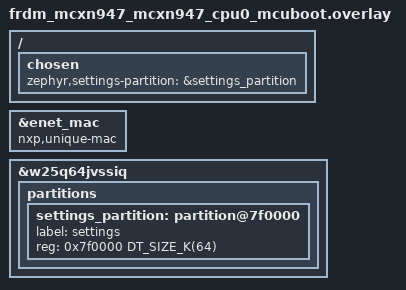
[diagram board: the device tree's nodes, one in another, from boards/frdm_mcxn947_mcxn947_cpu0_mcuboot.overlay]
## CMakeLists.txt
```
# SPDX-License-Identifier: Apache-2.0

cmake_minimum_required(VERSION 3.20.0)

find_package(Zephyr REQUIRED HINTS $ENV{ZEPHYR_BASE})
project(mqtt_tls)

# boards/<board>_mcuboot.overlay moves the settings into a partition that is
# only free when MCUboot owns the flash layout. Without the bootloader the
# image would be linked over it.
if(FILE_SUFFIX STREQUAL "mcuboot" AND NOT CONFIG_BOOTLOADER_MCUBOOT)
  message(FATAL_ERROR
    "FILE_SUFFIX=mcuboot needs CONFIG_BOOTLOADER_MCUBOOT: build with --sysbuild, "
    "or add -DEXTRA_CONF_FILE=overlay-mcuboot.conf for an existing MCUboot.")
endif()

target_sources(app PRIVATE
  src/main.c
  src/net_wait.c
  src/mqtt_app.c
  src/device_id.c
  src/commands.c
  src/config.c
  src/log_mqtt.c
  src/mgmt.c
)
target_sources_ifdef(CONFIG_APP_WATCHDOG app PRIVATE src/watchdog.c)

if(CONFIG_APP_MQTT_TLS)
  target_sources(app PRIVATE src/tls_creds.c)
  # tls_creds.c parses the credentials with mbedTLS at boot.
  target_link_libraries(app PRIVATE mbedTLS)

  # Embed the TLS credentials named in Kconfig into the image. Each file is
  # turned into a C byte list (<name>.inc) that src/tls_creds.c includes.
  # Relative paths are resolved against the application directory.
  # PEM files get a NUL terminator appended in C, which mbedTLS requires to
  # recognise the PEM format; DER files (*.der) are embedded as-is.
  set(gen_dir ${ZEPHYR_BINARY_DIR}/include/generated/app_creds)

  function(app_embed_credential kconfig_value name required)
    if("${kconfig_value}" STREQUAL "")
      if(required)
        message(FATAL_ERROR "${name}: no credential file configured")
      endif()
      return()
    endif()

    if(IS_ABSOLUTE "${kconfig_value}")
      set(path "${kconfig_value}")
    else()
      set(path "${APPLICATION_SOURCE_DIR}/${kconfig_value}")
    endif()

    if(NOT EXISTS "${path}")
      message(FATAL_ERROR
        "${name}: credential file '${path}' does not exist.\n"
        "Set the matching CONFIG_APP_MQTT_TLS_* option, or generate "
        "development credentials with apps/mqtt_tls/scripts/gen_dev_certs.sh.")
    endif()

    string(TOLOWER "${name}" lname)
    generate_inc_file_for_target(app "${path}" "${gen_dir}/${lname}.inc")
    target_compile_definitions(app PRIVATE APP_HAVE_${name}=1)

    get_filename_component(ext "${path}" LAST_EXT)
    string(TOLOWER "${ext}" ext)
    if(NOT ext STREQUAL ".der")
      target_compile_definitions(app PRIVATE APP_${name}_IS_PEM=1)
    endif()
  endfunction()

  app_embed_credential("${CONFIG_APP_MQTT_TLS_CA_CERT_FILE}" CA_CERT TRUE)

  if(CONFIG_APP_MQTT_TLS_CLIENT_AUTH)
    app_embed_credential("${CONFIG_APP_MQTT_TLS_CLIENT_CERT_FILE}" CLIENT_CERT TRUE)
    app_embed_credential("${CONFIG_APP_MQTT_TLS_CLIENT_KEY_FILE}" CLIENT_KEY TRUE)
  endif()

  target_include_directories(app PRIVATE ${gen_dir})
endif()
```

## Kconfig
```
# SPDX-License-Identifier: Apache-2.0

mainmenu "MQTT over Ethernet + TLS application"

menu "MQTT application"

config APP_MQTT_BROKER_HOSTNAME
	string "Broker host name or IPv4 address"
	default "test.mosquitto.org"
	help
	  Resolved with DNS before every connection attempt, so a broker that
	  moves to a new address is picked up on the next reconnect.

config APP_MQTT_BROKER_PORT
	int "Broker TCP port"
	default 8883 if APP_MQTT_TLS
	default 1883
	range 1 65535

config APP_MQTT_CLIENT_ID
	string "MQTT client identifier"
	default ""
	help
	  Leave empty to derive a stable identifier from the MCU's unique
	  device ID: APP_MQTT_CLIENT_ID_PREFIX followed by 20 base32
	  characters (the 96-bit STM32 UID as is; longer UIDs, such as the
	  128-bit NXP MCX UID, condensed to 96 bits with SHA-256), so every
	  board gets its own id without per-device configuration. Must not contain '+', '#' or
	  '/', since it is also a topic level.

config APP_MQTT_CLIENT_ID_PREFIX
	string "Prefix of the derived client identifier"
	default "z"
	help
	  MQTT 3.1.1 brokers are only required to accept client identifiers
	  of 1-23 alphanumeric characters. With a 20-character device ID, a
	  prefix of up to 3 letters or digits stays within that limit. Most
	  brokers accept longer identifiers.

config APP_MQTT_TOPIC_ROOT
	string "Root of the device's topic tree"
	default "bacnet-uc"
	help
	  Topics are "<root>/<client id>/status", ".../info", ".../telemetry",
	  ".../cmd" and ".../event". May contain '/', but no wildcards and no
	  leading '$'.

	  Commands on ".../cmd" must be published without the retain flag:
	  retained commands are ignored, because the broker would replay them
	  after every reconnect.

config APP_MQTT_USERNAME
	string "User name (empty: none)"
	default ""

config APP_MQTT_PASSWORD
	string "Password (empty: none)"
	default ""
	help
	  Requires APP_MQTT_USERNAME (MQTT 3.1.1). Stored in the firmware
	  image in clear text, and sent in clear text on the wire unless both
	  APP_MQTT_TLS and APP_MQTT_TLS_PEER_VERIFY are enabled. Prefer client
	  certificates (APP_MQTT_TLS_CLIENT_AUTH) where the broker supports
	  them.

config APP_MQTT_PUBLISH_INTERVAL_SEC
	int "Telemetry publish interval (seconds)"
	default 10
	range 1 86400

config APP_MQTT_PUBLISH_QOS
	int "QoS of telemetry messages"
	default 1
	range 0 1
	help
	  QoS 1 makes the broker acknowledge each message and gives
	  at-least-once delivery from the broker to its subscribers. The
	  device itself keeps no outgoing queue and uses clean sessions, so a
	  message still in flight when the connection drops is lost either
	  way. QoS 2 is not offered for the same reason.

config APP_MQTT_CONNACK_TIMEOUT_MS
	int "Time to wait for CONNACK or SUBACK (ms)"
	default 10000
	range 1000 120000
	help
	  Applies after the TCP/TLS connection is up. The TCP connect and the
	  TLS handshake are bounded separately by
	  CONFIG_NET_SOCKETS_CONNECT_TIMEOUT and
	  CONFIG_NET_SOCKETS_TLS_CONNECT_TIMEOUT.

config APP_MQTT_RECONNECT_MIN_MS
	int "Initial reconnect back-off (ms)"
	default 1000
	range 100 600000

config APP_MQTT_RECONNECT_MAX_MS
	int "Maximum reconnect back-off (ms)"
	default 60000
	range 100 600000

config APP_MQTT_BUFFER_SIZE
	int "MQTT RX and TX buffer size (bytes)"
	default 2048
	range 1024 65535
	help
	  Upper bound for one outgoing MQTT packet and for the fixed and
	  variable header of an incoming one. Incoming payloads are read
	  separately (see APP_MQTT_MAX_PAYLOAD_SIZE).

config APP_MQTT_MAX_PAYLOAD_SIZE
	int "Largest command payload that is processed (bytes)"
	default 128
	range 1 4096
	help
	  Longer payloads on the command topic are read and discarded so the
	  connection stays in sync.

config APP_MQTT_TLS
	bool "Use TLS (MQTTS)"
	default y
	depends on MQTT_LIB_TLS

if APP_MQTT_TLS

config APP_MQTT_TLS_CA_CERT_FILE
	string "CA certificate used to verify the broker (PEM or .der)"
	default "certs/mosquitto.org.crt"
	help
	  Path is relative to the application directory unless absolute.
	  The default is the CA of the public test broker test.mosquitto.org.

	  Must be signed with SHA-256 or stronger: SHA-1 is not built in, so
	  roots that are self-signed with SHA-1 (e.g. "DigiCert Global Root
	  CA") cannot be loaded. Use a SHA-256 root or the SHA-256-signed
	  intermediate as trust anchor instead. The file is parsed at boot and
	  errors are reported there.

config APP_MQTT_TLS_PEER_VERIFY
	bool "Verify the broker certificate"
	default y
	help
	  Checks the broker's certificate chain against the CA and its name
	  against APP_MQTT_TLS_HOSTNAME. Validity dates are NOT checked
	  (CONFIG_MBEDTLS_HAVE_TIME_DATE is off, as the board has no trusted
	  clock at boot), so expired certificates are accepted.

	  Disabling this makes the connection vulnerable to
	  man-in-the-middle attacks. Only for bring-up.

config APP_MQTT_TLS_HOSTNAME
	string "Expected host name in the broker certificate, and SNI"
	default ""
	help
	  Sent as TLS Server Name Indication and matched against the broker
	  certificate. Leave empty to use APP_MQTT_BROKER_HOSTNAME. Set it
	  when the broker is addressed by IP address: an IP literal is then
	  sent as SNI, which RFC 6066 forbids and multi-tenant cloud brokers
	  reject.

config APP_MQTT_TLS_CLIENT_AUTH
	bool "Authenticate with a client certificate (mutual TLS)"

config APP_MQTT_TLS_CLIENT_CERT_FILE
	string "Client certificate (PEM or .der)"
	depends on APP_MQTT_TLS_CLIENT_AUTH
	default "certs/dev/client.crt"
	help
	  The default matches the output of scripts/gen_dev_certs.sh.

config APP_MQTT_TLS_CLIENT_KEY_FILE
	string "Client private key (unencrypted PEM or .der)"
	depends on APP_MQTT_TLS_CLIENT_AUTH
	default "certs/dev/client.key"
	help
	  The default matches the output of scripts/gen_dev_certs.sh.

	  The key is stored unencrypted in flash, and in the build directory
	  (zephyr/include/generated/app_creds). Protect it with flash read-out
	  protection (RDP) on production parts, or move it into a secure
	  element.

endif # APP_MQTT_TLS

config APP_WAIT_FOR_NETWORK
	bool "Wait for an IPv4 address before connecting"
	default y
	depends on NET_CONNECTION_MANAGER
	help
	  Uses the connection manager to wait until the default interface is
	  up and has an IPv4 address, and drops the MQTT session when the
	  network goes away.

config APP_WATCHDOG
	bool "Reboot if the main loop stalls"
	default y if $(dt_alias_enabled,watchdog0)
	depends on TASK_WDT
	help
	  Uses a task watchdog channel, backed by the hardware watchdog.
	  Every blocking call in the application is bounded well below the
	  timeout, so a reset means a genuine wedge.

config APP_WATCHDOG_TIMEOUT_SEC
	int "Watchdog timeout (seconds)"
	depends on APP_WATCHDOG
	default 120
	range 60 3600

config APP_CONFIG_FALLBACK_ATTEMPTS
	int "Connection attempts before new settings fall back"
	default 5
	range 1 100
	help
	  After a change of the broker, credentials, TLS host name, topic root
	  or keep-alive (MQTT config_set or SMP settings), the new configuration
	  is on trial. If it does not reach "online" within this many
	  connection attempts, the stored settings roll back to the last known
	  good configuration (or to the Kconfig defaults if none has worked
	  yet). The counter survives reboots.

config APP_LOG_MQTT
	bool "Publish log lines over MQTT"
	default y
	depends on LOG
	select LOG_OUTPUT
	help
	  Log backend that keeps recent lines in RAM for <root>/<id>/log and
	  the "logs" command. Lines are only captured if their module was
	  compiled in at that level (CONFIG_LOG_DEFAULT_LEVEL, CONFIG_APP_LOG_LEVEL):
	  mqtt/log_level can lower the threshold at run time, but not raise it
	  beyond what was compiled in.

config APP_LOG_MQTT_LEVEL
	int "Default level of the MQTT log topic (1=err 2=wrn 3=inf 4=dbg)"
	default 2
	range 1 4
	help
	  Log lines at or above this level are captured in RAM and published
	  on <root>/<id>/log. Changeable at run time (mqtt/log_level).

config APP_LOG_MQTT_RING_SIZE
	int "Log lines kept in RAM"
	default 32
	range 4 256

config APP_LOG_MQTT_RATE
	int "Log lines published per second (sustained)"
	default 5
	range 1 100

config APP_LOG_MQTT_BURST
	int "Log lines published in a burst"
	default 20
	range 1 256

config APP_SMP
	bool "Remote management over SMP (MCUmgr) on UDP"
	default y
	depends on NET_UDP && NET_SOCKETS
	imply NET_BUF
	imply ZCBOR
	imply MCUMGR
	imply MCUMGR_TRANSPORT_UDP
	imply MCUMGR_TRANSPORT_UDP_IPV4
	imply MCUMGR_GRP_OS
	imply MCUMGR_GRP_OS_INFO
	imply MCUMGR_GRP_OS_MCUMGR_PARAMS
	imply MCUMGR_GRP_SETTINGS
	imply MCUMGR_MGMT_NOTIFICATION_HOOKS
	imply MCUMGR_GRP_SETTINGS_ACCESS_HOOK
	help
	  SMP server on UDP port 1337 (CONFIG_MCUMGR_TRANSPORT_UDP_PORT), as
	  in the BACnet firmware: OS group (echo, reset, info), settings group
	  (runtime configuration, subtree mqtt/) and, in the MCUboot variant,
	  the image group for firmware updates. SMP over UDP is not
	  authenticated: keep it on the management network.

if APP_SMP && MCUMGR

# A full Ethernet payload: image uploads need fewer round trips, and smpmgr
# sizes its upload chunks from the MTU reported by mcumgr params.
configdefault MCUMGR_TRANSPORT_UDP_MTU
	default 1472

# mcumgr params reports this as buf_size, and clients size their frames from
# it: it must not exceed the UDP MTU.
configdefault MCUMGR_TRANSPORT_NETBUF_SIZE
	default 1472

configdefault MCUMGR_TRANSPORT_WORKQUEUE_STACK_SIZE
	default 3072

configdefault MCUMGR_GRP_SETTINGS_NAME_LEN
	default 32

configdefault MCUMGR_GRP_SETTINGS_VALUE_LEN
	default 64

endif

config APP_MCUBOOT_CONFIRM_TIMEOUT_SEC
	int "Seconds a test image has to reach online before it is reverted"
	depends on BOOTLOADER_MCUBOOT
	default 600
	range 60 86400

# Without sysbuild (overlay-mcuboot.conf with a separately built MCUboot) the
# app has to match the bootloader's swap mode; same choice as Kconfig.sysbuild.
choice MCUBOOT_BOOTLOADER_MODE
	default MCUBOOT_BOOTLOADER_MODE_SWAP_SCRATCH if BOARD_NUCLEO_F767ZI
endchoice

# Plain NUCLEO-F767ZI build: the image is linked at the start of the flash and
# must end below the settings partition at 0x180000 (nucleo_f767zi.overlay);
# with this the linker, not the first settings write, reports an overflow.
configdefault FLASH_LOAD_SIZE
	default 0x180000 if BOARD_NUCLEO_F767ZI && !USE_DT_CODE_PARTITION

config APP_DHCPV4
	bool "Start DHCPv4 on the default interface"
	default y
	depends on NET_DHCPV4 && !NET_CONFIG_SETTINGS
	help
	  When CONFIG_NET_CONFIG_SETTINGS is used instead, the net_config
	  library assigns the (static or DHCP) address.

endmenu

module = APP
module-str = app
source "subsys/logging/Kconfig.template.log_config"

source "Kconfig.zephyr"
```

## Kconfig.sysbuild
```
# SPDX-License-Identifier: Apache-2.0
#
# Sysbuild Kconfig (west build --sysbuild only). Same as the BACnet firmware:
# on NUCLEO-F767ZI the image slots consist of three 256 KiB sectors. In the
# default swap-using-offset mode the secondary slot must hold one extra
# sector; swap using the board's scratch partition keeps the full 768 KiB.

choice MCUBOOT_MODE
	default MCUBOOT_MODE_SWAP_SCRATCH if BOARD_NUCLEO_F767ZI
endchoice

source "share/sysbuild/Kconfig"
```

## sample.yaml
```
sample:
  description: MQTT 3.1.1 client over TLS 1.3/1.2 on wired Ethernet
  name: MQTT over Ethernet + TLS
common:
  build_only: true
  platform_allow:
    - nucleo_f767zi
    - frdm_mcxn947/mcxn947/cpu0
    - nucleo_h563zi
    - native_sim/native/64
  integration_platforms:
    - nucleo_f767zi
    - frdm_mcxn947/mcxn947/cpu0
  tags:
    - net
    - mqtt
    - tls
tests:
  app.mqtt_tls:
    tags:
      - tls
  # Compile check of the mutual-TLS path. The mosquitto.org CA stands in for
  # the client certificate and key, so this image is not meant to be run.
  app.mqtt_tls.mtls:
    extra_configs:
      - CONFIG_APP_MQTT_TLS_CLIENT_AUTH=y
      - CONFIG_APP_MQTT_TLS_CLIENT_CERT_FILE="certs/mosquitto.org.crt"
      - CONFIG_APP_MQTT_TLS_CLIENT_KEY_FILE="certs/mosquitto.org.crt"
  # Plain MQTT on port 1883, without the TLS stack (prj_plain.conf).
  app.mqtt_tls.plain:
    extra_args:
      - FILE_SUFFIX=plain
  # MCUboot variant: bootloader + signed image, SMP image group (sysbuild).
  app.mqtt_tls.mcuboot:
    sysbuild: true
    platform_allow:
      - nucleo_f767zi
      - frdm_mcxn947/mcxn947/cpu0
    extra_args:
      - FILE_SUFFIX=mcuboot
```

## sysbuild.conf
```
# SPDX-License-Identifier: Apache-2.0
#
# MCUboot variant, used only by `west build --sysbuild` (a plain `west build`,
# the release artifact, ignores this file and builds the app without a
# bootloader):
#
#   west build --sysbuild -b nucleo_f767zi apps/mqtt_tls -d build-f767-mcuboot \
#       -- -DFILE_SUFFIX=mcuboot
#   west flash -d build-f767-mcuboot      # MCUboot + signed app
#
# FILE_SUFFIX=mcuboot selects boards/<board>_mcuboot.overlay (settings in a
# partition that MCUboot leaves free). sysbuild/mqtt_tls.conf adds the image
# management, sysbuild/mcuboot.conf the bootloader logging. The swap mode per
# board is chosen in Kconfig.sysbuild (same as the BACnet firmware):
#   nucleo_f767zi              swap using scratch (256 KiB sectors)
#   frdm_mcxn947/mcxn947/cpu0  swap using offset (8 KiB sectors)
#
# The image is signed with the MCUboot development key (bootloader/mcuboot/
# root-ec-p256.pem, public in the MCUboot repository): anyone can sign an
# image this bootloader accepts, so NOT for production. For a product set
# SB_CONFIG_BOOT_SIGNATURE_KEY_FILE to your own key, kept out of the repo.
SB_CONFIG_BOOTLOADER_MCUBOOT=y
SB_CONFIG_BOOT_SIGNATURE_TYPE_ECDSA_P256=y
```

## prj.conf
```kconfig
# SPDX-License-Identifier: Apache-2.0
#
# MQTT 3.1.1 client over TLS 1.3/1.2 on wired Ethernet (Zephyr 4.4).
# prj_plain.conf is the same without TLS (build with -DFILE_SUFFIX=plain);
# keep the common sections of both files in sync.

# --- Logging -----------------------------------------------------------------
CONFIG_LOG=y
CONFIG_NET_LOG=y
CONFIG_LOG_BACKEND_SHOW_COLOR=n

# --- IP stack ----------------------------------------------------------------
CONFIG_NETWORKING=y
CONFIG_NET_IPV4=y
CONFIG_NET_IPV6=n
CONFIG_NET_TCP=y
CONFIG_NET_UDP=y
CONFIG_NET_DHCPV4=y
CONFIG_NET_SOCKETS=y
# DHCPv4 installs only the first DNS server it is offered, so a single
# resolver slot is all that is ever used.
CONFIG_DNS_RESOLVER=y
CONFIG_NET_MGMT=y
CONFIG_NET_MGMT_EVENT=y
CONFIG_NET_MGMT_EVENT_INFO=y
CONFIG_NET_CONNECTION_MANAGER=y
# Use only the net_/NET_/ZSOCK_ names; the POSIX-style compatibility names
# are slated for removal.
CONFIG_NET_NAMESPACE_COMPAT_MODE=n


# Bound the TCP connect, and separately the whole TLS handshake (including
# the software ECDHE and certificate verification, which take a while on a
# Cortex-M33 without crypto acceleration).
CONFIG_NET_SOCKETS_CONNECT_TIMEOUT=15000

# RX buffers: the TCP receive window is derived from the pool
# (NET_BUF_RX_COUNT * NET_BUF_DATA_SIZE / 3); the default 1.5 KB window lets
# the broker send only one segment per round trip, and the driver needs 12
# buffers per full-size frame. 96 buffers give a 4 KB window and room for 8
# frames.
CONFIG_NET_BUF_RX_COUNT=96
CONFIG_NET_PKT_RX_COUNT=24

# Ethernet TX runs inline on whichever thread produces the packet (RX thread
# for TCP ACKs, TCP work queue for retransmits, system work queue for DHCP),
# so their default stacks have only a few percent of headroom.
CONFIG_NET_RX_STACK_SIZE=2048
CONFIG_NET_TCP_WORKQ_STACK_SIZE=1536
CONFIG_SYSTEM_WORKQUEUE_STACK_SIZE=1536
CONFIG_NET_MGMT_EVENT_STACK_SIZE=1024

# --- MQTT --------------------------------------------------------------------
CONFIG_MQTT_LIB=y
CONFIG_MQTT_LIB_TLS=y
CONFIG_MQTT_KEEPALIVE=60

# --- TLS (mbedTLS) -----------------------------------------------------------
CONFIG_NET_SOCKETS_SOCKOPT_TLS=y
CONFIG_NET_SOCKETS_TLS_MAX_CONTEXTS=1
CONFIG_NET_SOCKETS_TLS_CONNECT_TIMEOUT=15000
CONFIG_TLS_CREDENTIALS=y
CONFIG_TLS_MAX_CREDENTIALS_NUMBER=4

CONFIG_MBEDTLS=y
CONFIG_MBEDTLS_ENABLE_HEAP=y
# Full 16 KB records: brokers are not required to honour the max_fragment_length
# extension (AWS IoT and many cloud brokers ignore it), and a server
# certificate chain easily exceeds a smaller record. mbedTLS allocates the input
# and output buffers (~2 x 16.7 KB) from its heap during a session.
CONFIG_MBEDTLS_SSL_MAX_CONTENT_LEN=16384
CONFIG_MBEDTLS_HEAP_SIZE=65536
CONFIG_MBEDTLS_PEM_PARSE_C=y
CONFIG_MBEDTLS_SSL_EXTENDED_MASTER_SECRET=y
# Send the broker host name as SNI; multi-tenant brokers (HiveMQ Cloud, EMQX
# Serverless, AWS IoT custom domains) select the tenant from it.
CONFIG_MBEDTLS_SSL_SERVER_NAME_INDICATION=y
CONFIG_MBEDTLS_ECP_NIST_OPTIM=y

# Mbed TLS 4 (Zephyr 4.4) is configured per ciphersuite; each one selects the
# PSA algorithms it needs. Forward-secret ECDHE with AES-GCM only.
# TLS 1.2:
CONFIG_MBEDTLS_CIPHERSUITE_TLS_ECDHE_ECDSA_WITH_AES_128_GCM_SHA256=y
CONFIG_MBEDTLS_CIPHERSUITE_TLS_ECDHE_ECDSA_WITH_AES_256_GCM_SHA384=y
CONFIG_MBEDTLS_CIPHERSUITE_TLS_ECDHE_RSA_WITH_AES_128_GCM_SHA256=y
CONFIG_MBEDTLS_CIPHERSUITE_TLS_ECDHE_RSA_WITH_AES_256_GCM_SHA384=y
# TLS 1.3 (preferred when the broker offers it):
CONFIG_MBEDTLS_SSL_PROTO_TLS1_3=y
CONFIG_MBEDTLS_SSL_TLS1_3_KEY_EXCHANGE_MODE_EPHEMERAL_ENABLED=y
CONFIG_MBEDTLS_CIPHERSUITE_TLS1_3_AES_128_GCM_SHA256=y
CONFIG_MBEDTLS_CIPHERSUITE_TLS1_3_AES_256_GCM_SHA384=y
# Curves: P-256 and P-384 for certificates (P-384 for e.g. Let's Encrypt E5/E6
# and AWS ECC CAs), X25519 and P-256 for the key exchange.
CONFIG_PSA_WANT_ECC_SECP_R1_256=y
CONFIG_PSA_WANT_ECC_SECP_R1_384=y
CONFIG_PSA_WANT_ECC_MONTGOMERY_255=y
# TLS 1.3 only allows RSA-PSS signatures, so RSA broker certificates (e.g.
# test.mosquitto.org) and RSA client keys need PSS. Mbed TLS 4.1's TLS 1.2
# client then fails against brokers that speak only TLS 1.2 with an RSA key;
# build those with overlay-tls12-rsa.conf.
CONFIG_MBEDTLS_X509_RSASSA_PSS_SUPPORT=y
CONFIG_PSA_WANT_ALG_RSA_OAEP=y
# SHA-1 is deliberately not enabled: roots self-signed with SHA-1 cannot be
# loaded (see README).

# Certificate validity dates are NOT checked: MBEDTLS_HAVE_TIME_DATE stays off
# because there is no trusted clock at boot. Enabling it also requires setting
# CLOCK_REALTIME (e.g. SNTP + clock_settime()) before the first handshake, or
# every certificate is rejected as not yet valid.

# The board's hardware TRNG (STM32 RNG, NXP ELS TRNG) backs sys_csrand_get()
# and the PSA random generator used by Mbed TLS. Never enable
# TEST_RANDOM_GENERATOR.
CONFIG_ENTROPY_GENERATOR=y

# --- Settings (runtime configuration, see src/config.c) ---------------------
CONFIG_FLASH=y
CONFIG_FLASH_MAP=y
CONFIG_ZMS=y
CONFIG_SETTINGS=y
CONFIG_SETTINGS_RUNTIME=y

# SMP (MCUmgr) on UDP 1337 is enabled by CONFIG_APP_SMP (default y).

# --- Application -------------------------------------------------------------
# mbedTLS runs the handshake (ECDHE + certificate verification) on the thread
# that calls connect(), which is main.
CONFIG_MAIN_STACK_SIZE=8192
CONFIG_EVENTS=y
CONFIG_HWINFO=y
CONFIG_GPIO=y
CONFIG_JSON_LIBRARY=y
```

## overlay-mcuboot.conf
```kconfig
# SPDX-License-Identifier: Apache-2.0
#
# App image for an MCUboot that is already on the board (built separately),
# without sysbuild:
#
#   west build -b nucleo_f767zi apps/mqtt_tls -- -DFILE_SUFFIX=mcuboot \
#       -DEXTRA_CONF_FILE=overlay-mcuboot.conf
#
# With `west build --sysbuild` this is done by sysbuild.conf and
# sysbuild/mqtt_tls.conf instead.
#
# Sign the image with the key of the MCUboot on the board, e.g.
#   -DCONFIG_MCUBOOT_SIGNATURE_KEY_FILE=\"/path/to/key.pem\"
# (the MCUboot development key is public: never use it in production). The
# swap mode must match the bootloader (Kconfig: swap using scratch on
# NUCLEO-F767ZI).
CONFIG_BOOTLOADER_MCUBOOT=y
CONFIG_STREAM_FLASH=y
CONFIG_IMG_MANAGER=y
CONFIG_MCUBOOT_IMG_MANAGER=y
CONFIG_MCUMGR_GRP_IMG=y
CONFIG_MCUMGR_GRP_OS_BOOTLOADER_INFO=y
# Erase slot1 sector by sector while the upload proceeds, instead of all at
# once on the first chunk (seconds with the CPU stalled on 256 KiB sectors).
CONFIG_IMG_ERASE_PROGRESSIVELY=y
```

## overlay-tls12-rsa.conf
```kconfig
# SPDX-License-Identifier: Apache-2.0
#
# For brokers that speak only TLS 1.2 and use an RSA key. With TLS 1.3 enabled
# the client offers RSA-PSS signatures, which such a broker (OpenSSL) picks for
# its TLS 1.2 key exchange, and Mbed TLS 4.1's TLS 1.2 client rejects them
# (alert illegal_parameter). This overlay restricts the device to TLS 1.2 with
# PKCS#1 v1.5 RSA signatures.
#
#   west build ... -- -DEXTRA_CONF_FILE=overlay-tls12-rsa.conf
CONFIG_MBEDTLS_SSL_PROTO_TLS1_3=n
CONFIG_MBEDTLS_SSL_TLS1_3_KEY_EXCHANGE_MODE_EPHEMERAL_ENABLED=n
CONFIG_MBEDTLS_CIPHERSUITE_TLS1_3_AES_128_GCM_SHA256=n
CONFIG_MBEDTLS_CIPHERSUITE_TLS1_3_AES_256_GCM_SHA384=n
CONFIG_MBEDTLS_X509_RSASSA_PSS_SUPPORT=n
```

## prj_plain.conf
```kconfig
# SPDX-License-Identifier: Apache-2.0
#
# Plain-TCP variant of prj.conf (no TLS, port 1883), for debugging against a
# local broker only. Build with -DFILE_SUFFIX=plain. Keep the common sections
# of both files in sync.

# --- Logging -----------------------------------------------------------------
CONFIG_LOG=y
CONFIG_NET_LOG=y
CONFIG_LOG_BACKEND_SHOW_COLOR=n

# --- IP stack ----------------------------------------------------------------
CONFIG_NETWORKING=y
CONFIG_NET_IPV4=y
CONFIG_NET_IPV6=n
CONFIG_NET_TCP=y
CONFIG_NET_UDP=y
CONFIG_NET_DHCPV4=y
CONFIG_NET_SOCKETS=y
# DHCPv4 installs only the first DNS server it is offered, so a single
# resolver slot is all that is ever used.
CONFIG_DNS_RESOLVER=y
CONFIG_NET_MGMT=y
CONFIG_NET_MGMT_EVENT=y
CONFIG_NET_MGMT_EVENT_INFO=y
CONFIG_NET_CONNECTION_MANAGER=y
# Use only the net_/NET_/ZSOCK_ names; the POSIX-style compatibility names
# are slated for removal.
CONFIG_NET_NAMESPACE_COMPAT_MODE=n

# SO_RCVTIMEO/SO_SNDTIMEO on plain TCP sockets (TLS sockets handle them in the
# TLS layer).
CONFIG_NET_CONTEXT_RCVTIMEO=y
CONFIG_NET_CONTEXT_SNDTIMEO=y

# Bounds the TCP connect.
CONFIG_NET_SOCKETS_CONNECT_TIMEOUT=15000

# RX buffers: the TCP receive window is derived from the pool
# (NET_BUF_RX_COUNT * NET_BUF_DATA_SIZE / 3); the default 1.5 KB window lets
# the broker send only one segment per round trip, and the driver needs 12
# buffers per full-size frame. 96 buffers give a 4 KB window and room for 8
# frames.
CONFIG_NET_BUF_RX_COUNT=96
CONFIG_NET_PKT_RX_COUNT=24

# Ethernet TX runs inline on whichever thread produces the packet (RX thread
# for TCP ACKs, TCP work queue for retransmits, system work queue for DHCP),
# so their default stacks have only a few percent of headroom.
CONFIG_NET_RX_STACK_SIZE=2048
CONFIG_NET_TCP_WORKQ_STACK_SIZE=1536
CONFIG_SYSTEM_WORKQUEUE_STACK_SIZE=1536
CONFIG_NET_MGMT_EVENT_STACK_SIZE=1024

# --- MQTT --------------------------------------------------------------------
CONFIG_MQTT_LIB=y
CONFIG_MQTT_LIB_TLS=n
CONFIG_MQTT_KEEPALIVE=60

# --- Settings (runtime configuration, see src/config.c) ---------------------
CONFIG_FLASH=y
CONFIG_FLASH_MAP=y
CONFIG_ZMS=y
CONFIG_SETTINGS=y
CONFIG_SETTINGS_RUNTIME=y

# --- Application -------------------------------------------------------------
# Random back-off jitter comes from the hardware TRNG.
CONFIG_ENTROPY_GENERATOR=y
CONFIG_MAIN_STACK_SIZE=4096
CONFIG_EVENTS=y
CONFIG_HWINFO=y
CONFIG_GPIO=y
CONFIG_JSON_LIBRARY=y
```

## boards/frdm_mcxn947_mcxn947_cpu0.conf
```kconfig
# SPDX-License-Identifier: Apache-2.0
# FRDM-MCXN947 (cpu0): ENET QoS + LAN PHY (generic MII), ELS TRNG, WWDT.

# Task watchdog backed by the WWDT (alias watchdog0). The WWDT runs from the
# 1 MHz FRO with a fixed /4 prescaler (max ~67 s); give the HW fallback a wide
# margin over the task_wdt kernel timer instead of the default 100 + 20 ms.
CONFIG_WATCHDOG=y
CONFIG_TASK_WDT=y
CONFIG_TASK_WDT_MIN_TIMEOUT=1000
CONFIG_TASK_WDT_HW_FALLBACK_DELAY=1000

# ENET QoS RX ring: with 128-byte net_bufs a 1518-byte frame takes 12
# descriptors, so the default 16 holds a single full-size frame. 48 keep four.
# The driver permanently reserves one RX net_buf per descriptor.
CONFIG_ETH_NXP_ENET_QOS_RX_BUFFER_DESCRIPTORS=48
CONFIG_NET_BUF_RX_COUNT=128
```

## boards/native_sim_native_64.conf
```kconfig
# SPDX-License-Identifier: Apache-2.0
#
# Host test target: native_sim with offloaded sockets (NSOS). The Zephyr socket
# API is mapped onto the host's BSD sockets, so the application reaches a broker
# on the host (or the internet) without TAP interfaces or root privileges. TLS
# still runs in Zephyr's mbedTLS on top of the offloaded TCP socket.
CONFIG_ETH_NATIVE_TAP=n
CONFIG_NET_DRIVERS=y
CONFIG_NET_SOCKETS_OFFLOAD=y
CONFIG_NET_NATIVE_OFFLOADED_SOCKETS=y
CONFIG_HEAP_MEM_POOL_SIZE=4096

# The offloaded interface has no Zephyr-managed address: no DHCP, and don't
# wait for L4 connectivity, which it never reports. (The connection manager
# itself stays, since MCUmgr's UDP transport selects it.)
CONFIG_NET_DHCPV4=n
CONFIG_APP_WAIT_FOR_NETWORK=n
# NSOS sizes struct net_sockaddr for AF_UNIX (110 bytes); the SMP UDP
# transport keeps the peer address in the net_buf user data.
CONFIG_MCUMGR_TRANSPORT_NETBUF_USER_DATA_SIZE=112
```

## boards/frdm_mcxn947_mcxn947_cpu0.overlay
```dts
/* SPDX-License-Identifier: Apache-2.0 */

/* Stable per-chip MAC (NXP OUI with the locally administered bit, plus the
 * CRC-24 of the 128-bit UID) instead of a new random MAC on every boot, which
 * would also mean a new DHCP lease after every watchdog reset.
 */
&enet_mac {
	/delete-property/ zephyr,random-mac-address;
	nxp,unique-mac;
};
```

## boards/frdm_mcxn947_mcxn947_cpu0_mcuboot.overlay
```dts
/* SPDX-License-Identifier: Apache-2.0 */

/* Stable per-chip MAC (NXP OUI with the locally administered bit, plus the
 * CRC-24 of the 128-bit UID) instead of a new random MAC on every boot, which
 * would also mean a new DHCP lease after every watchdog reset.
 */
&enet_mac {
	/delete-property/ zephyr,random-mac-address;
	nxp,unique-mac;
};

/* Runtime settings: the last 64 KiB of the external W25Q64 NOR flash
 * (4 KiB sectors), in both the plain and the MCUboot variant. The internal
 * flash is fully taken by MCUboot and its two slots. The board's
 * storage_partition spans the whole W25Q64 and is used by other firmware on
 * this board (BACnet); keeping to the top 64 KiB means switching firmware
 * does not wipe each other's settings, as long as they stay below 0x7F0000.
 */
/delete-node/ &storage_partition;

&w25q64jvssiq {
	partitions {
		settings_partition: partition@7f0000 {
			label = "settings";
			reg = <0x7f0000 DT_SIZE_K(64)>;
		};
	};
};

/ {
	chosen {
		zephyr,settings-partition = &settings_partition;
	};
};
```

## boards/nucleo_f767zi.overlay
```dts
/* SPDX-License-Identifier: Apache-2.0 */

/* PA7 is RMII CRS_DV; the board DTS also enables SPI1 with MOSI on PA7. */
&spi1 {
	status = "disabled";
};

/* Runtime settings (plain build, no MCUboot): the image is linked at the
 * start of the flash and covers the board's storage_partition, so settings go
 * to the last two 256 KiB sectors instead. slot1/scratch are only used with
 * MCUboot (the MCUboot variant uses boards/nucleo_f767zi_mcuboot.overlay).
 */
/delete-node/ &slot1_partition;
/delete-node/ &scratch_partition;

&flash0 {
	partitions {
		settings_partition: partition@180000 {
			label = "settings";
			reg = <0x00180000 DT_SIZE_K(512)>;
		};
	};
};

/ {
	chosen {
		zephyr,settings-partition = &settings_partition;
	};
};
```

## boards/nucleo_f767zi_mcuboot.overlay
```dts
/* SPDX-License-Identifier: Apache-2.0 */

/* MCUboot variant (FILE_SUFFIX=mcuboot): MCUboot in boot_partition, the image
 * in slot0, updates via slot1 + scratch. Runtime settings use the board's
 * storage_partition (2 x 32 KiB sectors @0x10000), which is free here.
 */

/* PA7 is RMII CRS_DV; the board DTS also enables SPI1 with MOSI on PA7. */
&spi1 {
	status = "disabled";
};

/ {
	chosen {
		zephyr,settings-partition = &storage_partition;
	};
};
```

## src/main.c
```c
/*
 * SPDX-License-Identifier: Apache-2.0
 *
 * MQTT over Ethernet + TLS for STM32 and NXP MCX boards.
 *
 * main() waits for the network, runs MQTT sessions back to back and applies
 * an exponential back-off with jitter between failed attempts, so a fleet of
 * devices does not reconnect in lock-step after a broker outage.
 */

#include <errno.h>
#include <string.h>

#include <zephyr/kernel.h>
#include <zephyr/logging/log.h>
#include <zephyr/random/random.h>

#include "app.h"

LOG_MODULE_REGISTER(app, CONFIG_APP_LOG_LEVEL);

BUILD_ASSERT(CONFIG_APP_MQTT_RECONNECT_MIN_MS > 0 &&
	     CONFIG_APP_MQTT_RECONNECT_MIN_MS <= CONFIG_APP_MQTT_RECONNECT_MAX_MS,
	     "invalid reconnect back-off range");

/* Exponential back-off; each delay is randomised to 75..125 % of the base. */
static uint32_t next_backoff(uint32_t *backoff_ms)
{
	uint32_t base = *backoff_ms;
	uint32_t jitter = base / 2U;
	uint32_t delay = base - base / 4U + (jitter ? sys_rand32_get() % jitter : 0U);

	*backoff_ms = MIN(base * 2U, (uint32_t)CONFIG_APP_MQTT_RECONNECT_MAX_MS);

	return delay;
}

/* Sleep without starving the watchdog. */
static void sleep_fed(uint32_t ms)
{
	while (ms > 0U) {
		uint32_t chunk = MIN(ms, 5000U);

		app_wdt_feed();
		k_sleep(K_MSEC(chunk));
		ms -= chunk;
	}
	app_wdt_feed();
}

int main(void)
{
	uint32_t backoff_ms = CONFIG_APP_MQTT_RECONNECT_MIN_MS;
	int ret;

	LOG_INF("MQTT over Ethernet + TLS on %s", CONFIG_BOARD);

	app_commands_init();
	app_mgmt_init();

	/* Kconfig defaults overlaid with stored settings (runtime config). */
	(void)app_config_init();

	ret = app_mqtt_init();
	if (ret < 0) {
		LOG_ERR("Invalid configuration, MQTT client not started");
		return ret;
	}

#if defined(CONFIG_APP_MQTT_TLS)
	ret = app_tls_creds_register();
	if (ret < 0) {
		LOG_ERR("Invalid TLS credentials, MQTT client not started");
		return ret;
	}
#endif

	/* Armed only once the configuration is known to be usable, so a
	 * misconfigured device logs its error instead of reboot-looping.
	 */
	ret = app_wdt_init();
	if (ret < 0) {
		return ret;
	}

	app_net_init();

	while (true) {
		bool healthy;
		uint32_t delay;

		if (!app_net_is_up()) {
			LOG_INF("Waiting for network...");
			while (app_net_wait_up(K_SECONDS(5)) != 0) {
				app_wdt_feed();
			}
		}

		ret = app_mqtt_run_session(&healthy);
		if (healthy) {
			backoff_ms = CONFIG_APP_MQTT_RECONNECT_MIN_MS;
		}

		delay = next_backoff(&backoff_ms);
		LOG_WRN("Session ended (%d), reconnecting in %u ms", ret, delay);
		sleep_fed(delay);
	}

	return 0;
}
```

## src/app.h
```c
/*
 * SPDX-License-Identifier: Apache-2.0
 */

#ifndef APP_H_
#define APP_H_

#include <stdbool.h>
#include <stddef.h>
#include <stdint.h>
#include <zephyr/kernel.h>
#include <zephyr/net/tls_credentials.h>

/* config.c ------------------------------------------------------------------ */

/** Longest string setting, including the terminating NUL. */
#define APP_CFG_STR_LEN 64

/** Runtime configuration: Kconfig defaults overlaid with stored settings. */
struct app_config {
	char broker_host[APP_CFG_STR_LEN];
	char tls_hostname[APP_CFG_STR_LEN]; /* empty: use broker_host */
	char username[APP_CFG_STR_LEN];
	char password[APP_CFG_STR_LEN];
	char topic_root[APP_CFG_STR_LEN];
	uint32_t publish_interval; /* seconds */
	uint16_t broker_port;
	uint16_t keepalive;        /* seconds */
	uint8_t log_level;         /* LOG_LEVEL_* threshold for the MQTT log topic */
};

/** Load stored settings on top of the Kconfig defaults. */
int app_config_init(void);

/** Snapshot of the current configuration. */
void app_config_get(struct app_config *out);

/** Snapshot plus the mask of keys that are stored (not Kconfig defaults). */
void app_config_snapshot(struct app_config *out, uint32_t *mask);

/**
 * Validate, store and apply one key. @p next_connect tells whether the change
 * takes effect only on the next connection. Returns 0, -ENOENT (unknown key),
 * -EINVAL or -ENAMETOOLONG (bad value) or -EIO (storage failed). A new
 * log_level is applied immediately.
 */
int app_config_set(const char *name, const char *value, bool *next_connect);

/** Current value of one key as text; secrets read as "***". */
int app_config_get_value(const char *name, char *buf, size_t len);

/** Delete all stored settings: back to the Kconfig defaults (applied now). */
int app_config_reset(void);

/** The whole configuration as a JSON object (secrets masked). Length or -ENOMEM. */
int app_config_json(char *buf, size_t len);

/** Comma-separated JSON strings of all key names, for caps.config. */
void app_config_key_list(char *buf, size_t len);

/**
 * Call before each connection attempt. Counts down a trial of new connection
 * settings; returns true if it just fell back to the last known good.
 */
bool app_config_attempt(void);

/** topic_root of the last known good configuration, or "" if there is none. */
void app_config_lkg_topic_root(char *buf, size_t len);

/**
 * Call when a session reached "online". @p used (with its stored-key mask
 * @p used_mask, both from app_config_snapshot) is the configuration that
 * session connected with; it becomes the last known good.
 */
void app_config_online(const struct app_config *used, uint32_t used_mask);

/* net_wait.c ---------------------------------------------------------------- */

/** Register for connectivity events and start address configuration. */
void app_net_init(void);

/** True while the default interface is up and has an IPv4 address. */
bool app_net_is_up(void);

/** Block until the network is up or @p timeout expires. 0 or -EAGAIN. */
int app_net_wait_up(k_timeout_t timeout);

/* device_id.c --------------------------------------------------------------- */

/**
 * Write the MQTT client identifier into @p buf (NUL-terminated).
 * Returns 0, or -ENOSPC if @p len is too small.
 */
int app_client_id_get(char *buf, size_t len);

/** Write the MCU unique ID in hex (NUL-terminated), or "unknown". */
void app_hwid_get(char *buf, size_t len);

/* tls_creds.c --------------------------------------------------------------- */

/** Security tag under which all of the application's credentials live. */
#define APP_TLS_SEC_TAG 0x4d5154 /* "MQT" */

/** Check and register the embedded CA (and client) credentials. */
int app_tls_creds_register(void);

/* watchdog.c ---------------------------------------------------------------- */

#if defined(CONFIG_APP_WATCHDOG)
/** Arm the task watchdog channel for the main loop. */
int app_wdt_init(void);

/** Tell the watchdog that the main loop is making progress. */
void app_wdt_feed(void);
#else
static inline int app_wdt_init(void)
{
	return 0;
}

static inline void app_wdt_feed(void)
{
}
#endif

/* mqtt_app.c ---------------------------------------------------------------- */

/** One-time client setup (topics, client id). */
int app_mqtt_init(void);

/**
 * Run one MQTT session: resolve, connect, serve until the connection is lost.
 *
 * @param[out] was_connected set to true if the broker accepted the session
 *             and it stayed up long enough to count as healthy, so the
 *             caller can reset its back-off.
 * @return negative errno describing why the session ended.
 */
int app_mqtt_run_session(bool *was_connected);

/* log_mqtt.c ---------------------------------------------------------------- */

/** One log line captured for the MQTT log topic. */
struct app_log_line {
	uint32_t t_ms;   /* uptime */
	uint8_t level;   /* LOG_LEVEL_ERR .. LOG_LEVEL_DBG */
	char src[20];    /* log module */
	char msg[120];
};

/** Threshold for lines captured by the MQTT log backend (LOG_LEVEL_*). */
void app_log_set_level(uint8_t level);

/**
 * Fetch the next line after @p cursor (a running line number, 0 = first ever).
 * @p lost is set to the number of lines that fell out of the ring before they
 * were read. Returns false when there is nothing new.
 */
bool app_log_next(uint32_t *cursor, struct app_log_line *out, uint32_t *lost);

/** Number of lines captured since boot. */
uint32_t app_log_count(void);

const char *app_log_level_name(uint8_t level);

/** One line as a JSON object. Length, or -ENOMEM. */
int app_log_line_json(const struct app_log_line *line, uint32_t lost, char *buf, size_t len);

/** Copy @p src into @p dst as the body of a JSON string. Returns the length. */
size_t app_json_escape(char *dst, size_t len, const char *src);

/* mgmt.c -------------------------------------------------------------------- */

/**
 * Note whether this is an unconfirmed MCUboot test image; if so, schedule the
 * revert reboot (cancelled by app_mgmt_online).
 */
void app_mgmt_init(void);

/** The device reached "online": confirm a test image. */
void app_mgmt_online(void);

/** The "mgmt" and "boot" members of the info message (no braces). */
int app_mgmt_info_json(char *buf, size_t len);

/* mqtt_app.c (continued) ------------------------------------------------------ */

/** End the current session after the pending reply; reconnect with new settings. */
void app_mqtt_request_reconnect(void);

/* (log_mqtt.c) The last @p n log lines as a JSON array member
 * "logs":[...] into @p buf, as many as fit. Returns the number of lines.
 */
int app_log_last_json(size_t n, char *buf, size_t len);

/* commands.c ---------------------------------------------------------------- */

/** Set up the LED used by the led and identify commands. */
void app_commands_init(void);

/**
 * Execute a command received on the command topic (plain text or JSON) and
 * write the JSON reply. @p payload is NUL-terminated and modified in place.
 */
void app_handle_command(char *payload, char *reply, size_t reply_len);

/** Write the "caps" JSON object announced in the retained info message. */
void app_commands_caps(char *buf, size_t len);

#endif /* APP_H_ */
```

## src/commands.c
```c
/*
 * SPDX-License-Identifier: Apache-2.0
 *
 * Commands received on <root>/<id>/cmd, in either form:
 *
 *   plain text   "<cmd>[ <arg>]", e.g. "identify 30", "config_set keepalive=30"
 *   JSON         {"id":"<=16 chars","cmd":"led","arg":"on"}
 *
 * Commands: ping, led on|off|toggle, identify [s], config_get [key],
 * config_set key=value, config_reset, reconnect, logs [n].
 *
 * Replies go to <root>/<id>/event as JSON: {"ok":true,...} or
 * {"ok":false,"error":"..."}; a JSON request's "id" is echoed so a client
 * can match replies when several clients send commands.
 */

#include <ctype.h>
#include <errno.h>
#include <stdlib.h>
#include <string.h>

#include <zephyr/data/json.h>
#include <zephyr/drivers/gpio.h>
#include <zephyr/kernel.h>
#include <zephyr/logging/log.h>
#include <zephyr/sys/util.h>

#include "app.h"

LOG_MODULE_DECLARE(app, CONFIG_APP_LOG_LEVEL);

#define REQUEST_ID_MAX_LEN 16
#define IDENTIFY_DEFAULT_SEC 30
#define IDENTIFY_MAX_SEC 3600
#define IDENTIFY_BLINK_MS 250

#if DT_NODE_HAS_STATUS(DT_ALIAS(led0), okay)
#define HAVE_LED 1
static const struct gpio_dt_spec led = GPIO_DT_SPEC_GET(DT_ALIAS(led0), gpios);
#else
#define HAVE_LED 0
#endif

/* The LED is driven from the MQTT thread (commands) and the system work
 * queue (identify blinking).
 */
static K_MUTEX_DEFINE(led_lock);
static bool led_ready;
static bool led_state;        /* commanded state, restored after identify */
static int64_t identify_until; /* 0 when not identifying */
static bool blink_on;
static struct k_work_delayable identify_work;

static void led_write(bool on)
{
#if HAVE_LED
	(void)gpio_pin_set_dt(&led, on ? 1 : 0);
#else
	ARG_UNUSED(on);
#endif
}

static void identify_handler(struct k_work *work)
{
	ARG_UNUSED(work);

	k_mutex_lock(&led_lock, K_FOREVER);
	if (identify_until == 0 || k_uptime_get() >= identify_until) {
		identify_until = 0;
		led_write(led_state);
	} else {
		blink_on = !blink_on;
		led_write(blink_on);
		k_work_reschedule(&identify_work, K_MSEC(IDENTIFY_BLINK_MS));
	}
	k_mutex_unlock(&led_lock);
}

void app_commands_init(void)
{
	k_work_init_delayable(&identify_work, identify_handler);

#if HAVE_LED
	if (!gpio_is_ready_dt(&led)) {
		LOG_WRN("LED not ready");
		return;
	}
	if (gpio_pin_configure_dt(&led, GPIO_OUTPUT_INACTIVE) == 0) {
		led_ready = true;
	}
#endif
}

static int led_set(bool on)
{
	if (!led_ready) {
		return -ENODEV;
	}

	k_mutex_lock(&led_lock, K_FOREVER);
	identify_until = 0; /* an explicit LED command ends identify */
	led_state = on;
	led_write(on);
	k_mutex_unlock(&led_lock);

	return 0;
}

static int identify(uint32_t seconds)
{
	if (!led_ready) {
		return -ENODEV;
	}

	k_mutex_lock(&led_lock, K_FOREVER);
	identify_until = (seconds == 0U) ? 0 : k_uptime_get() + (int64_t)seconds * MSEC_PER_SEC;
	k_mutex_unlock(&led_lock);

	/* Stopping also runs the handler once, which restores the LED. */
	k_work_reschedule(&identify_work, K_NO_WAIT);

	return 0;
}

#define LOGS_DEFAULT 10
#define LOGS_MAX 50

struct result {
	bool ok;
	const char *error;
	char *detail;      /* extra JSON members, without braces */
	size_t detail_len;
};

static const char *config_error(int err)
{
	switch (err) {
	case -ENOENT:
		return "unknown key";
	case -EINVAL:
		return "bad value";
	case -ENAMETOOLONG:
		return "value too long";
	default:
		return "storage error";
	}
}

static void execute_config(const char *cmd, char *arg, struct result *r)
{
	int ret;

	if (strcmp(cmd, "config_get") == 0) {
		if (arg == NULL) {
			int n = snprintk(r->detail, r->detail_len, "\"config\":");

			ret = app_config_json(&r->detail[n], r->detail_len - n);
			if (ret < 0) {
				r->error = "reply too long";
				return;
			}
		} else {
			char value[APP_CFG_STR_LEN];

			ret = app_config_get_value(arg, value, sizeof(value));
			if (ret < 0) {
				r->error = config_error(ret);
				return;
			}
			snprintk(r->detail, r->detail_len, "\"key\":\"%s\",\"value\":\"%s\"",
				 arg, value);
		}
		r->ok = true;
		return;
	}

	if (strcmp(cmd, "config_set") == 0) {
		char *value = (arg != NULL) ? strchr(arg, '=') : NULL;
		bool next_connect;

		if (value == NULL) {
			r->error = "bad argument";
			return;
		}
		*value++ = '\0';
		ret = app_config_set(arg, value, &next_connect);
		if (ret < 0) {
			r->error = config_error(ret);
			return;
		}
		r->ok = true;
		snprintk(r->detail, r->detail_len, "\"key\":\"%s\",\"applies\":\"%s\"", arg,
			 next_connect ? "next_connect" : "now");
		return;
	}

	if (strcmp(cmd, "config_reset") == 0 && arg == NULL) {
		(void)app_config_reset();
		r->ok = true;
		snprintk(r->detail, r->detail_len,
			 "\"config\":\"defaults\",\"applies\":\"next_connect\"");
		return;
	}

	r->error = "unknown command";
}

static void execute(const char *cmd, char *arg, struct result *r)
{
	int ret;

	r->ok = false;
	r->error = NULL;
	r->detail[0] = '\0';

	if (strncmp(cmd, "config_", 7) == 0) {
		execute_config(cmd, arg, r);
		return;
	}

	if (strcmp(cmd, "reconnect") == 0 && arg == NULL) {
		/* The reply goes out first; the session ends afterwards. */
		app_mqtt_request_reconnect();
		r->ok = true;
		snprintk(r->detail, r->detail_len, "\"reconnect\":true");
		return;
	}

	if (strcmp(cmd, "logs") == 0) {
		unsigned long n = LOGS_DEFAULT;

		if (arg != NULL) {
			char *end;

			n = strtoul(arg, &end, 10);
			if (*arg == '\0' || *end != '\0' || n == 0 || n > LOGS_MAX) {
				r->error = "bad argument";
				return;
			}
		}
		ret = app_log_last_json(n, r->detail, r->detail_len);
		if (ret < 0) {
			r->error = "reply too long";
			return;
		}
		r->ok = true;
		return;
	}

	if (strcmp(cmd, "ping") == 0 && arg == NULL) {
		r->ok = true;
		snprintk(r->detail, r->detail_len, "\"pong\":%u", k_uptime_seconds());
		return;
	}

	if (strcmp(cmd, "led") == 0) {
		bool on;

		if (arg != NULL && strcmp(arg, "on") == 0) {
			on = true;
		} else if (arg != NULL && strcmp(arg, "off") == 0) {
			on = false;
		} else if (arg != NULL && strcmp(arg, "toggle") == 0) {
			on = !led_state;
		} else {
			r->error = "bad argument";
			return;
		}
		ret = led_set(on);
		if (ret < 0) {
			r->error = "led unavailable";
			return;
		}
		r->ok = true;
		snprintk(r->detail, r->detail_len, "\"led\":%s", on ? "true" : "false");
		return;
	}

	if (strcmp(cmd, "identify") == 0) {
		unsigned long seconds = IDENTIFY_DEFAULT_SEC;

		if (arg != NULL) {
			char *end;

			seconds = strtoul(arg, &end, 10);
			if (*arg == '\0' || *end != '\0' || seconds > IDENTIFY_MAX_SEC) {
				r->error = "bad argument";
				return;
			}
		}
		ret = identify((uint32_t)seconds);
		if (ret < 0) {
			r->error = "led unavailable";
			return;
		}
		r->ok = true;
		snprintk(r->detail, r->detail_len, "\"identify\":%lu", seconds);
		return;
	}

	r->error = "unknown command";
}

struct json_request {
	const char *id;
	const char *cmd;
	const char *arg;
};

static const struct json_obj_descr json_request_descr[] = {
	JSON_OBJ_DESCR_PRIM(struct json_request, id, JSON_TOK_STRING),
	JSON_OBJ_DESCR_PRIM(struct json_request, cmd, JSON_TOK_STRING),
	JSON_OBJ_DESCR_PRIM(struct json_request, arg, JSON_TOK_STRING),
};

/* The id is echoed into the reply unescaped, so it is restricted to
 * characters that need no escaping in JSON.
 */
static bool is_valid_request_id(const char *id)
{
	size_t len = strlen(id);

	if (len == 0U || len > REQUEST_ID_MAX_LEN) {
		return false;
	}
	for (size_t i = 0U; i < len; i++) {
		char c = id[i];

		if (!(isalnum((unsigned char)c) || c == '-' || c == '_' || c == '.' ||
		      c == ':')) {
			return false;
		}
	}

	return true;
}

static void format_reply(char *reply, size_t reply_len, const char *id,
			 const struct result *r)
{
	char id_member[REQUEST_ID_MAX_LEN + 8] = "";

	if (id != NULL) {
		snprintk(id_member, sizeof(id_member), "\"id\":\"%s\",", id);
	}

	if (r->ok) {
		snprintk(reply, reply_len, "{%s\"ok\":true%s%s}", id_member,
			 r->detail[0] != '\0' ? "," : "", r->detail);
	} else {
		snprintk(reply, reply_len, "{%s\"ok\":false,\"error\":\"%s\"}", id_member,
			 r->error);
	}
}

void app_handle_command(char *payload, char *reply, size_t reply_len)
{
	/* Commands run on the MQTT thread only, one at a time. */
	static char detail[CONFIG_APP_MQTT_BUFFER_SIZE - 256];
	struct result r = { .detail = detail, .detail_len = sizeof(detail) };

	if (payload[0] == '{') {
		struct json_request req = { 0 };
		const char *id = NULL;
		int64_t fields;

		/* Decodes in place; strings point into payload. */
		fields = json_obj_parse(payload, strlen(payload), json_request_descr,
					ARRAY_SIZE(json_request_descr), &req);
		/* Echo the id whenever it is usable, also in error replies. */
		if (fields >= 0 && (fields & BIT(0)) && is_valid_request_id(req.id)) {
			id = req.id;
		}
		r.ok = false;
		detail[0] = '\0';
		if (fields < 0) {
			r.error = "invalid json";
		} else if ((fields & BIT(0)) && id == NULL) {
			r.error = "invalid id";
		} else if (!(fields & BIT(1))) {
			r.error = "missing cmd";
		} else {
			execute(req.cmd, (fields & BIT(2)) ? (char *)req.arg : NULL, &r);
		}
		format_reply(reply, reply_len, id, &r);
		return;
	}

	/* Plain text: "<cmd>[ <arg>]" */
	char *arg = strchr(payload, ' ');

	if (arg != NULL) {
		*arg++ = '\0';
	}
	execute(payload, arg, &r);
	format_reply(reply, reply_len, NULL, &r);
}

void app_commands_caps(char *buf, size_t len)
{
	char keys[192];

	app_config_key_list(keys, sizeof(keys));

	/* Commands the harness can offer; LED commands only with an LED. */
	snprintk(buf, len,
		 "{\"cmds\":[\"ping\"%s,\"config\",\"reconnect\",\"logs\"],"
		 "\"config\":[%s],"
		 "\"telemetry\":{\"seq\":\"count\",\"uptime_s\":\"s\",\"sessions\":\"count\"}}",
		 led_ready ? ",\"led\",\"identify\"" : "", keys);
}
```
